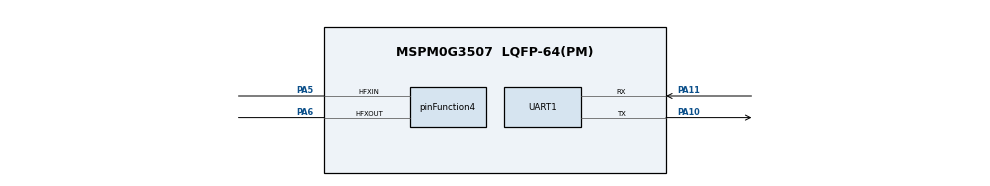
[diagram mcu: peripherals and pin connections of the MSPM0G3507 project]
/**
 * These arguments were used when this file was generated. They will be automatically applied on subsequent loads
 * via the GUI or CLI. Run CLI with '--help' for additional information on how to override these arguments.
 * @cliArgs --device "MSPM0G350X" --part "Default" --package "LQFP-64(PM)" --product "mspm0_sdk@2.10.00.04"
 * @v2CliArgs --device "MSPM0G3507" --package "LQFP-64(PM)" --product "mspm0_sdk@2.10.00.04"
 * @versions {"tool":"1.26.2+4477"}
 */

/**
 * Import the modules used in this configuration.
 */
const GPIO          = scripting.addModule("/ti/driverlib/GPIO", {}, false);
const GPIO1         = GPIO.addInstance();
const MCAN          = scripting.addModule("/ti/driverlib/MCAN", {}, false);
const MCAN1         = MCAN.addInstance();
const SYSCTL        = scripting.addModule("/ti/driverlib/SYSCTL");
const SYSTICK       = scripting.addModule("/ti/driverlib/SYSTICK");
const UART          = scripting.addModule("/ti/driverlib/UART", {}, false);
const UART1         = UART.addInstance();
const ProjectConfig = scripting.addModule("/ti/project_config/ProjectConfig");

/**
 * Write custom configuration values to the imported modules.
 */
const divider9       = system.clockTree["UDIV"];
divider9.divideValue = 2;

const multiplier2         = system.clockTree["PLL_QDIV"];
multiplier2.multiplyValue = 4;

const mux4       = system.clockTree["EXHFMUX"];
mux4.inputSelect = "EXHFMUX_XTAL";

const mux5       = system.clockTree["EXLFMUX"];
mux5.inputSelect = "EXLFMUX_XTAL";

const mux8       = system.clockTree["HSCLKMUX"];
mux8.inputSelect = "HSCLKMUX_SYSPLL0";

const mux9       = system.clockTree["LFXTMUX"];
mux9.inputSelect = "LFXTMUX_TRUE";

const mux10       = system.clockTree["MFPCLKMUX"];
mux10.inputSelect = "MFPCLKMUX_HFCLK";

const mux12       = system.clockTree["SYSPLLMUX"];
mux12.inputSelect = "zSYSPLLMUX_HFCLK";

const pinFunction4                        = system.clockTree["HFXT"];
pinFunction4.inputFreq                    = 40;
pinFunction4.enable                       = true;
pinFunction4.HFXTStartup                  = 10;
pinFunction4.peripheral.$assign           = "SYSCTL";
pinFunction4.peripheral.hfxInPin.$assign  = "PA5";
pinFunction4.peripheral.hfxOutPin.$assign = "PA6";

const pinFunction6     = system.clockTree["LFXT"];
pinFunction6.inputFreq = 32.768;
pinFunction6.enable    = true;

GPIO1.$name                              = "LED";
GPIO1.port                               = "PORTB";
GPIO1.associatedPins[0].$name            = "LED_PIN";
GPIO1.associatedPins[0].assignedPin      = "22";
GPIO1.associatedPins[0].internalResistor = "PULL_UP";

const Board = scripting.addModule("/ti/driverlib/Board", {}, false);

MCAN1.$name              = "MCAN0";
MCAN1.fdMode             = false;
MCAN1.enableInterrupt    = true;
MCAN1.spPercent          = 85;
MCAN1.desiredDataRate    = 0;
MCAN1.stdFiltType        = "10";
MCAN1.extFiltType        = "10";
MCAN1.txBufElemSize      = "DL_MCAN_ELEM_SIZE_8BYTES";
MCAN1.txBufNum           = 8;
MCAN1.rxFIFO0size        = 8;
MCAN1.rxFIFO1OpMode      = "1";
MCAN1.rxFIFO0ElemSize    = "DL_MCAN_ELEM_SIZE_8BYTES";
MCAN1.rxFIFO1ElemSize    = "DL_MCAN_ELEM_SIZE_8BYTES";
MCAN1.interruptFlags     = ["DL_MCAN_INTERRUPT_RF0N"];
MCAN1.extFiltElem        = "001";
MCAN1.stdFiltElem        = "001";
MCAN1.interruptLine      = ["DL_MCAN_INTR_LINE_NUM_0"];
MCAN1.interruptLine0Flag = ["DL_MCAN_INTERRUPT_RF0N"];
MCAN1.m0interrupts       = ["DL_MCAN_MSP_INTERRUPT_LINE0"];
MCAN1.txFIFOSize         = 8;
MCAN1.txPinConfig.$name  = "ti_driverlib_gpio_GPIOPinGeneric0";
MCAN1.rxPinConfig.$name  = "ti_driverlib_gpio_GPIOPinGeneric1";

SYSCTL.forceDefaultClkConfig = true;
SYSCTL.clockTreeEn           = true;

SYSTICK.periodEnable    = true;
SYSTICK.period          = 80000;
SYSTICK.interruptEnable = true;
SYSTICK.systickEnable   = true;

UART1.$name                          = "UART_0";
UART1.targetBaudRate                 = 115200;
UART1.calculatedBaudRate             = 1;
UART1.enabledDMATXTriggers           = "DL_UART_DMA_INTERRUPT_TX";
UART1.enabledDMARXTriggers           = "DL_UART_DMA_INTERRUPT_RX";
UART1.rxFifoThreshold                = "DL_UART_RX_FIFO_LEVEL_ONE_ENTRY";
UART1.enableFIFO                     = true;
UART1.rxTimeoutValue                 = 10;
UART1.enabledInterrupts              = ["DMA_DONE_RX","DMA_DONE_TX","EOT_DONE"];
UART1.peripheral.rxPin.$assign       = "PA11";
UART1.peripheral.txPin.$assign       = "PA10";
UART1.txPinConfig.$name              = "ti_driverlib_gpio_GPIOPinGeneric2";
UART1.rxPinConfig.$name              = "ti_driverlib_gpio_GPIOPinGeneric3";
UART1.DMA_CHANNEL_TX.addressMode     = "b2f";
UART1.DMA_CHANNEL_TX.srcLength       = "BYTE";
UART1.DMA_CHANNEL_TX.dstLength       = "BYTE";
UART1.DMA_CHANNEL_TX.$name           = "DMA_CH0";
UART1.DMA_CHANNEL_TX.enableInterrupt = true;
UART1.DMA_CHANNEL_RX.addressMode     = "f2b";
UART1.DMA_CHANNEL_RX.srcLength       = "BYTE";
UART1.DMA_CHANNEL_RX.dstLength       = "BYTE";
UART1.DMA_CHANNEL_RX.transferSize    = 4096;
UART1.DMA_CHANNEL_RX.$name           = "DMA_CH1";
UART1.DMA_CHANNEL_RX.enableInterrupt = true;

ProjectConfig.genLibCMSIS = true;

/**
 * Pinmux solution for unlocked pins/peripherals. This ensures that minor changes to the automatic solver in a future
 * version of the tool will not impact the pinmux you originally saw.  These lines can be completely deleted in order to
 * re-solve from scratch.
 */
pinFunction6.peripheral.$suggestSolution           = "SYSCTL";
pinFunction6.peripheral.lfxInPin.$suggestSolution  = "PA3";
pinFunction6.peripheral.lfxOutPin.$suggestSolution = "PA4";
GPIO1.associatedPins[0].pin.$suggestSolution       = "PB22";
Board.peripheral.$suggestSolution                  = "DEBUGSS";
Board.peripheral.swclkPin.$suggestSolution         = "PA20";
Board.peripheral.swdioPin.$suggestSolution         = "PA19";
MCAN1.peripheral.$suggestSolution                  = "CANFD0";
MCAN1.peripheral.rxPin.$suggestSolution            = "PA13";
MCAN1.peripheral.txPin.$suggestSolution            = "PA12";
UART1.peripheral.$suggestSolution                  = "UART0";
UART1.DMA_CHANNEL_TX.peripheral.$suggestSolution   = "DMA_CH1";
UART1.DMA_CHANNEL_RX.peripheral.$suggestSolution   = "DMA_CH0";
